# N569S register map
File version: 1.0
Registers are 32-bit, read-write, reset 0x0 unless marked. A register's access mark holds for its fields unless they carry their own. Offsets are from the block's base; [hi:lo] are bit positions; 'fields as' and 'values as' point back to an identical list.

## SYS — SYS Register Map
Base 0x50000000
0x00 SYS_PDID ro reset not defined — Product Identifier Register
  [15:0] IMG2 — Product Identifier. Data in MAP2 of information block are copied to this register after power on. MAP2 is used to store part number defined by Nuvoton.
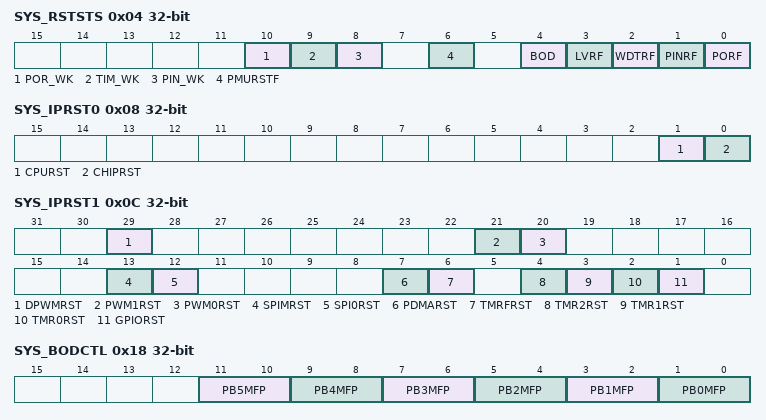
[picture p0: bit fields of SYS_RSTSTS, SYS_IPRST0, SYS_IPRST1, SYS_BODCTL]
0x04 SYS_RSTSTS (reset mask 0xFFFFF000) — System Reset Source Register
  [10] POR_WK — Wakeup from DPD From POR. The device was woken from Deep Power Down by a Power On Reset.
    0=No wakeup from POR; 1=The device was issued a wakeup from DPD by a POR
  [9] TIM_WK — Wakeup from DPD From TIMER. The device was woken from Deep Power Down by count of 10kHz timer.
    0=No wakeup from TIMER; 1=The device was issued a wakeup from DPD by a TIMER event
  [8] PIN_WK — Wakeup from DPD From PIN. The device was woken from Deep Power Down by a low transition on the WAKEUP in or RESETB pin. Note: Write 1 to this register to clear all wakeup flags.
    0=No wakeup from PIN; 1=The device was issued a wakeup from DPD by a pin transition
  [6] PMURSTF — Reset Source From PMU. The PMURSTF flag is set by the reset signal from the PMU module to indicate the previous reset source. Note: Write 1 to clear this bit to 0.
    0=No reset from PMU; 1=The PMU has issued the reset signal to reset the system
  [4] BOD — BOD Reset Flag. The BOD reset flag is set by the "Reset Signal" from the Brown Out Reset Controller to indicate the previous reset source. Note: Write 1 to clear this bit to 0.
    0=No reset from BOD; 1=BOD controller had issued the reset signal to reset the system
  [3] LVRF — LVR Reset Flag. The LVR reset flag is set by the "Reset Signal" from the Low Voltage Reset Controller to indicate the previous reset source. Note: Write 1 to clear this bit to 0.
    0=No reset from LVR; 1=LVR controller had issued the reset signal to reset the system
  [2] WDTRF — Reset Source From WDG. The WDTRF flag is set if pervious reset source originates from the Watch-Dog module. Note: Write 1 to clear this bit to 0.
    0=No reset from Watch-Dog; 1=The Watch-Dog module issued the reset signal to reset the system
  [1] PINRF — RESETB Pin Reset Flag. The RESETB pin reset flag is set by the "Reset Signal" from the RESETB Pin to indicate the previous reset source. Note: Write 1 to clear this bit to 0.
    0=No reset from RESETB pin; 1=Pin RESETB had issued the reset signal to reset the system
  [0] PORF — POR Reset Flag. The POR reset flag is set by the "Reset Signal" from the Power-on Reset (POR) Controller to indicate the previous reset source. Note: Write 1 to clear this bit to 0.
    0=No reset from POR; 1=Power-on Reset (POR) Controller had issued the reset signal to reset the system
0x08 SYS_IPRST0 — IP Reset Control Resister0
  [1] CPURST — CPU Kernel One Shot Reset. Setting this bit will reset the CPU kernel and Flash Memory Controller(FMC), this bit will automatically return to "0" after the 2 clock cycles
    0=Normal; 1=Reset CPU
  [0] CHIPRST — CHIP One Shot Reset. Set this bit will reset the whole chip, this bit will automatically return to "0" after 2 clock cycles. CHIPRST is same as POR reset, all the chip modules are reset and the chip configuration settings from Flash Memory are reloaded.
    0=Normal; 1=Reset CHIP
0x0C SYS_IPRST1 — IP Reset Control Resister1
  [29] DPWMRST — DPWM Controller Reset
    0=Normal Operation; 1=Reset
  [21] PWM1RST — PWM1 Controller Reset
    0=Normal Operation; 1=Reset
  [20] PWM0RST — PWM0 Controller Reset
    0=Normal Operation; 1=Reset
  [13] SPIMRST — SPIM Controller Reset
    0=Normal Operation; 1=Reset
  [12] SPI0RST — SPI0 Controller Reset
    0=Normal Operation; 1=Reset
  [7] PDMARST — PDMA Controller Reset
    0=Normal operation; 1=Reset
  [6] TMRFRST — TimerF Controller Reset
    0=Normal operation; 1=Reset
  [4] TMR2RST — Timer2 Controller Reset
    0=Normal operation; 1=Reset
  [3] TMR1RST — Timer1 Controller Reset
    0=Normal Operation; 1=Reset
  [2] TMR0RST — Timer0 Controller Reset
    0=Normal Operation; 1=Reset
  [1] GPIORST — GPIO Controller Reset
    0=Normal operation; 1=Reset
0x18 SYS_BODCTL (reset mask 0xFFF0FF00) — Brown-out Detector Control Register
  [11:10] PB5MFP — PB.5 Multi-function Pin Selection
  [9:8] PB4MFP — PB.4 Multi-function Pin Selection
  [7:6] PB3MFP — PB.3 Multi-function Pin Selection
  [5:4] PB2MFP — PB.2 Multi-function Pin Selection
  [3:2] PB1MFP — PB.1 Multi-function Pin Selection
  [1:0] PB0MFP — PB.0 Multi-function Pin Selection
0x30 SYS_GPA_MFP reset 0x55000000 — GPIO PA Multiple Alternate Functions and Input Type Control Register
0x34 SYS_GPB_MFP — GPIO PB Multiple Alternate Functions and Input Type Control Register
0x38 SYS_ICE_MFP reset 0x1 — ICE Multi-function-pin Controller Register
  [0] ICE_EN — This bit will set ICE_CLK & ICE_DAT pins to be serial debug wires or PA.6/7
    0=ICE_CLK and ICE_DAT will be assigned as PA.6 and PA.7, for general IO purpose; 1=ICE_CLK and ICE_DAT will be set as ICE CLOCK/ ICE DIO, only for debugging purpose
0x40 SYS_GPIO_INTP reset 0xFFF — GPIO Input Type and Slew Rate Ontrol
0x44 SYS_GPA_PULL — PA.15 ~ PA.0 Pull Resistance Control Register
  [0] IEN
    0=Input buffer Enabled; 1=Input buffer disabled, and input signal always equals to 0
0x4C SYS_GPA_IEN reset 0xF000 — PA.15 ~ PA.0 Digital and Analog Input Buffer Control Register
0x54 SYS_GPB_PULL — PB.5 ~ PB.0 Pull Resistance Control Register
  fields as SYS_GPA_PULL
0x5C SYS_GPB_IEN — PB.5 ~ PB.0 Digital Input Buffer Control Register
0xF0 SYS_IMGMAP3 ro reset not defined — MAP3 Data Image Register
  [31:0] IMG3 — Data Image of MAP3. Data in MAP3 of information block are copied to this register after power on.
0xF4 SYS_DEVICEID ro reset 0x3571 — Device ID Register
  [15:0] DEVICEID — Device ID Data. This register provides specific read-only information for the Device ID
0xF8 SYS_IMGMAP0 ro reset not defined — MAP0 Data Image Register
  [31:0] IMG0 — Data Image of MAP0. Data in MAP0 of information block are copied to this register after power on.
0xFC SYS_IMGMAP1 ro reset not defined — MAP1 Data Image Register
  [31:0] IMG1 — Data Image of MAP1. Data in MAP1 of information block are copied to this register after power on.
0x100 SYS_REGLCTL — Register Lock Control Register
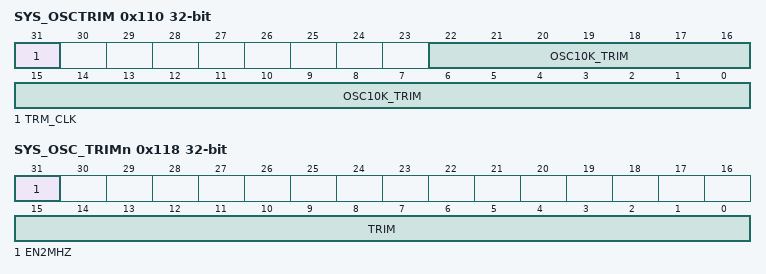
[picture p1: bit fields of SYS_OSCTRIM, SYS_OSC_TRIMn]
0x110 SYS_OSCTRIM reset not defined — Internal Oscillator Trim Register
  [31] TRM_CLK — Must be toggled to load a new OSC10K_TRIM
  [22:0] OSC10K_TRIM — 23bit trim for 10kHz oscillator.
0x114 SYS_OSC10K reset not defined — 10kHz oscillator and bias trim register
0x118 SYS_OSC_TRIMn reset not defined — Internal Oscillator Trim Register
  [31] EN2MHZ — 1: Low Frequency mode of oscillator active (2MHz). 0: High frequency mode (20-50MHz)
  [15:0] TRIM — 16bit sign extended representation of 10bit trim. OSC_TRIM[0] maps to above-mentioned OSCTRIM. OSC_TRIM[1] & OSC_TRIM[2] are reserved.
